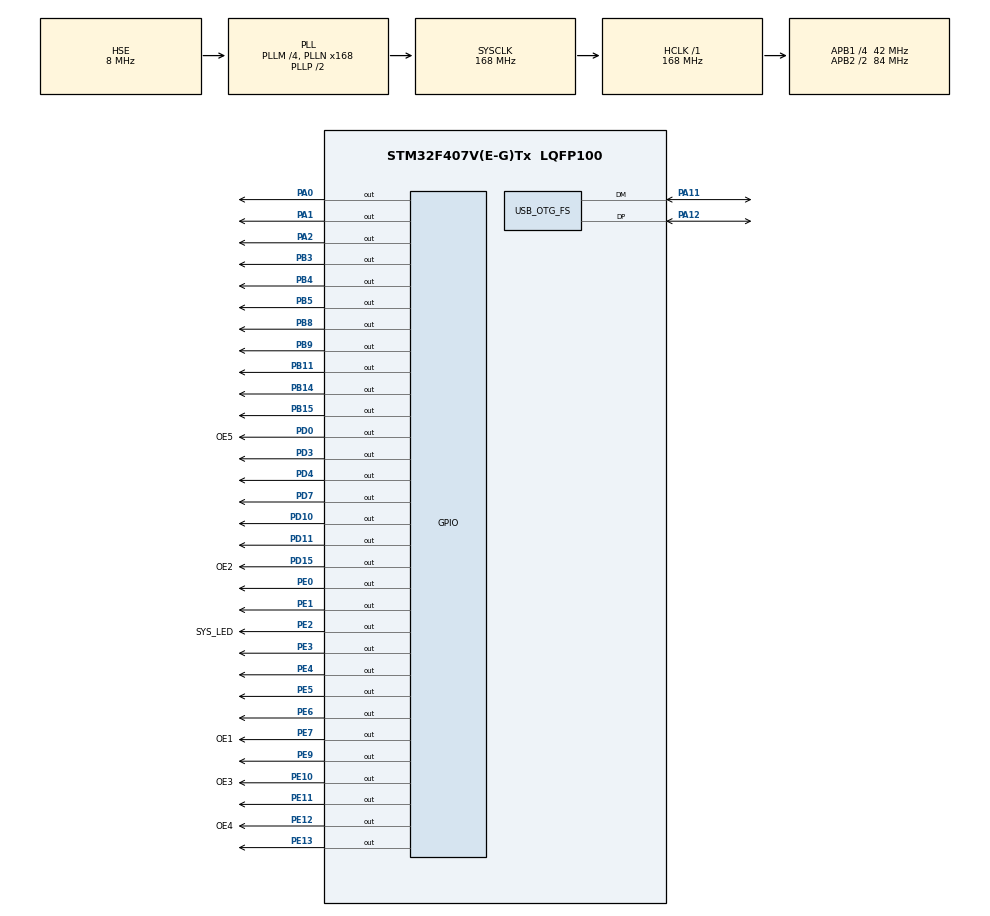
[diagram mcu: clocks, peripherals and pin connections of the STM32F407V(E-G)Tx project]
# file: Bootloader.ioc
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FREERTOS.Tasks01=defaultTask,24,128,StartDefaultTask,Default,NULL,Dynamic,NULL,NULL
Mcu.Family=STM32F4
Mcu.Name=STM32F407V(E-G)Tx
Mcu.Package=LQFP100
NVIC.OTG_FS_IRQn=true\:5\:0\:false\:false\:true\:true\:true\:true\:true
NVIC.PriorityGroup=NVIC_PRIORITYGROUP_4
PA0-WKUP.GPIO_PuPd=GPIO_PULLDOWN
PA0-WKUP.Signal=GPIO_Output
PA1.GPIO_PuPd=GPIO_PULLDOWN
PA1.Signal=GPIO_Output
PA11.Mode=Device_Only
PA11.Signal=USB_OTG_FS_DM
PA12.Mode=Device_Only
PA12.Signal=USB_OTG_FS_DP
PA2.GPIO_PuPd=GPIO_PULLDOWN
PA2.Signal=GPIO_Output
PB11.GPIO_PuPd=GPIO_PULLDOWN
PB11.Signal=GPIO_Output
PB14.GPIO_PuPd=GPIO_PULLDOWN
PB14.Signal=GPIO_Output
PB15.GPIO_PuPd=GPIO_PULLDOWN
PB15.Signal=GPIO_Output
PB3.GPIO_PuPd=GPIO_PULLDOWN
PB3.Signal=GPIO_Output
PB4.GPIO_PuPd=GPIO_PULLDOWN
PB4.Signal=GPIO_Output
PB5.GPIO_PuPd=GPIO_PULLDOWN
PB5.Signal=GPIO_Output
PB8.GPIO_PuPd=GPIO_PULLDOWN
PB8.Signal=GPIO_Output
PB9.GPIO_PuPd=GPIO_PULLDOWN
PB9.Signal=GPIO_Output
PD0.GPIO_Label=OE5
PD0.GPIO_PuPd=GPIO_NOPULL
PD0.GPIO_Speed=GPIO_SPEED_FREQ_MEDIUM
PD0.Signal=GPIO_Output
PD10.GPIO_PuPd=GPIO_PULLDOWN
PD10.Signal=GPIO_Output
PD11.GPIO_PuPd=GPIO_PULLDOWN
PD11.Signal=GPIO_Output
PD15.GPIO_Label=OE2
PD15.Signal=GPIO_Output
PD3.GPIO_PuPd=GPIO_PULLDOWN
PD3.Signal=GPIO_Output
PD4.GPIO_PuPd=GPIO_PULLDOWN
PD4.Signal=GPIO_Output
PD7.GPIO_PuPd=GPIO_PULLDOWN
PD7.Signal=GPIO_Output
PE0.GPIO_PuPd=GPIO_PULLDOWN
PE0.Signal=GPIO_Output
PE1.GPIO_PuPd=GPIO_PULLDOWN
PE1.Signal=GPIO_Output
PE10.GPIO_Label=OE3
PE10.GPIO_Speed=GPIO_SPEED_FREQ_MEDIUM
PE10.Signal=GPIO_Output
PE11.GPIO_PuPd=GPIO_PULLDOWN
PE11.Signal=GPIO_Output
PE12.GPIO_Label=OE4
PE12.GPIO_PuPd=GPIO_NOPULL
PE12.GPIO_Speed=GPIO_SPEED_FREQ_MEDIUM
PE12.Signal=GPIO_Output
PE13.GPIO_PuPd=GPIO_PULLDOWN
PE13.Signal=GPIO_Output
PE2.GPIO_Label=SYS_LED
PE2.GPIO_PuPd=GPIO_PULLUP
PE2.GPIO_Speed=GPIO_SPEED_FREQ_HIGH
PE2.PinState=GPIO_PIN_SET
PE2.Signal=GPIO_Output
PE3.GPIO_PuPd=GPIO_PULLDOWN
PE3.Signal=GPIO_Output
PE4.GPIO_PuPd=GPIO_PULLDOWN
PE4.Signal=GPIO_Output
PE5.GPIO_PuPd=GPIO_PULLDOWN
PE5.Signal=GPIO_Output
PE6.GPIO_PuPd=GPIO_PULLDOWN
PE6.Signal=GPIO_Output
PE7.GPIO_Label=OE1
PE7.GPIO_Speed=GPIO_SPEED_FREQ_MEDIUM
PE7.Signal=GPIO_Output
PE9.GPIO_PuPd=GPIO_PULLDOWN
PE9.Signal=GPIO_Output
PH0-OSC_IN.Mode=HSE-External-Oscillator
PH0-OSC_IN.Signal=RCC_OSC_IN
PH1-OSC_OUT.Mode=HSE-External-Oscillator
PH1-OSC_OUT.Signal=RCC_OSC_OUT
ProjectManager.HeapSize=0x1000
ProjectManager.StackSize=0x1000
ProjectManager.TargetToolchain=MDK-ARM V5.27
RCC.48MHZClocksFreq_Value=48000000
RCC.AHBFreq_Value=168000000
RCC.APB1CLKDivider=RCC_HCLK_DIV4
RCC.APB1Freq_Value=42000000
RCC.APB1TimFreq_Value=84000000
RCC.APB2CLKDivider=RCC_HCLK_DIV2
RCC.APB2Freq_Value=84000000
RCC.APB2TimFreq_Value=168000000
RCC.CortexFreq_Value=168000000
RCC.HCLKFreq_Value=168000000
RCC.HSE_VALUE=8000000
RCC.HSI_VALUE=16000000
RCC.LSE_VALUE=32768
RCC.PLLM=4
RCC.PLLN=168
RCC.PLLQ=7
RCC.SYSCLKFreq_VALUE=168000000
RCC.SYSCLKSource=RCC_SYSCLKSOURCE_PLLCLK
RCC.VCOOutputFreq_Value=336000000
USB_DEVICE.CLASS_NAME_FS=CDC
USB_DEVICE.VirtualMode-CDC_FS=Cdc
USB_DEVICE.VirtualModeFS=Cdc_FS
USB_OTG_FS.VirtualMode=Device_Only
VP_FREERTOS_VS_CMSIS_V2.Mode=CMSIS_V2
VP_USB_DEVICE_VS_USB_DEVICE_CDC_FS.Mode=CDC_FS
board=custom

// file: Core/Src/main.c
/* USER CODE BEGIN Header */
/**
  ******************************************************************************
  * @file           : main.c
  * @brief          : Main program body
  ******************************************************************************
  * @attention
  *
  * Copyright (c) 2024 STMicroelectronics.
  * All rights reserved.
  *
  * This software is licensed under terms that can be found in the LICENSE file
  * in the root directory of this software component.
  * If no LICENSE file comes with this software, it is provided AS-IS.
  *
  ******************************************************************************
  */
/* USER CODE END Header */
#include "main.h"
#include "cmsis_os.h"
#include "usb_device.h"

/* USER CODE BEGIN Includes */
#include "app.h"
/* USER CODE END Includes */

/* Definitions for defaultTask */
osThreadId_t defaultTaskHandle;
const osThreadAttr_t defaultTask_attributes = {
  .name = "defaultTask",
  .stack_size = 128 * 4,
  .priority = (osPriority_t) osPriorityNormal,
};

void SystemClock_Config(void);
static void MX_GPIO_Init(void);
void StartDefaultTask(void *argument);

int main(void)
{

  /* MCU Configuration--------------------------------------------------------*/

  /* Reset of all peripherals, Initializes the Flash interface and the Systick. */
  HAL_Init();

  /* Configure the system clock */
  SystemClock_Config();

  /* Initialize all configured peripherals */
  MX_GPIO_Init();

  /* Init scheduler */
  osKernelInitialize();

  /* Create the thread(s) */
  /* creation of defaultTask */
  defaultTaskHandle = osThreadNew(StartDefaultTask, NULL, &defaultTask_attributes);

  /* Start scheduler */
  osKernelStart();

  /* We should never get here as control is now taken by the scheduler */
  /* Infinite loop */
  while (1)
  {

  }
}

void SystemClock_Config(void)
{
  RCC_OscInitTypeDef RCC_OscInitStruct = {0};
  RCC_ClkInitTypeDef RCC_ClkInitStruct = {0};

  /** Configure the main internal regulator output voltage
  */
  __HAL_RCC_PWR_CLK_ENABLE();
  __HAL_PWR_VOLTAGESCALING_CONFIG(PWR_REGULATOR_VOLTAGE_SCALE1);

  /** Initializes the RCC Oscillators according to the specified parameters
  * in the RCC_OscInitTypeDef structure.
  */
  RCC_OscInitStruct.OscillatorType = RCC_OSCILLATORTYPE_HSE;
  RCC_OscInitStruct.HSEState = RCC_HSE_ON;
  RCC_OscInitStruct.PLL.PLLState = RCC_PLL_ON;
  RCC_OscInitStruct.PLL.PLLSource = RCC_PLLSOURCE_HSE;
  RCC_OscInitStruct.PLL.PLLM = 4;
  RCC_OscInitStruct.PLL.PLLN = 168;
  RCC_OscInitStruct.PLL.PLLP = RCC_PLLP_DIV2;
  RCC_OscInitStruct.PLL.PLLQ = 7;
  if (HAL_RCC_OscConfig(&RCC_OscInitStruct) != HAL_OK)
  {
    Error_Handler();
  }

  /** Initializes the CPU, AHB and APB buses clocks
  */
  RCC_ClkInitStruct.ClockType = RCC_CLOCKTYPE_HCLK|RCC_CLOCKTYPE_SYSCLK
                              |RCC_CLOCKTYPE_PCLK1|RCC_CLOCKTYPE_PCLK2;
  RCC_ClkInitStruct.SYSCLKSource = RCC_SYSCLKSOURCE_PLLCLK;
  RCC_ClkInitStruct.AHBCLKDivider = RCC_SYSCLK_DIV1;
  RCC_ClkInitStruct.APB1CLKDivider = RCC_HCLK_DIV4;
  RCC_ClkInitStruct.APB2CLKDivider = RCC_HCLK_DIV2;

  if (HAL_RCC_ClockConfig(&RCC_ClkInitStruct, FLASH_LATENCY_5) != HAL_OK)
  {
    Error_Handler();
  }
}

static void MX_GPIO_Init(void)
{
  GPIO_InitTypeDef GPIO_InitStruct = {0};

  /* GPIO Ports Clock Enable */
  __HAL_RCC_GPIOE_CLK_ENABLE();
  __HAL_RCC_GPIOH_CLK_ENABLE();
  __HAL_RCC_GPIOA_CLK_ENABLE();
  __HAL_RCC_GPIOB_CLK_ENABLE();
  __HAL_RCC_GPIOD_CLK_ENABLE();

  /*Configure GPIO pin Output Level */
  HAL_GPIO_WritePin(SYS_LED_GPIO_Port, SYS_LED_Pin, GPIO_PIN_SET);

  /*Configure GPIO pin Output Level */
  HAL_GPIO_WritePin(GPIOE, GPIO_PIN_3|GPIO_PIN_4|GPIO_PIN_5|GPIO_PIN_6
                          |OE1_Pin|GPIO_PIN_9|OE3_Pin|GPIO_PIN_11
                          |OE4_Pin|GPIO_PIN_13|GPIO_PIN_0|GPIO_PIN_1, GPIO_PIN_RESET);

  /*Configure GPIO pin Output Level */
  HAL_GPIO_WritePin(GPIOA, GPIO_PIN_0|GPIO_PIN_1|GPIO_PIN_2, GPIO_PIN_RESET);

  /*Configure GPIO pin Output Level */
  HAL_GPIO_WritePin(GPIOB, GPIO_PIN_11|GPIO_PIN_14|GPIO_PIN_15|GPIO_PIN_3
                          |GPIO_PIN_4|GPIO_PIN_5|GPIO_PIN_8|GPIO_PIN_9, GPIO_PIN_RESET);

  /*Configure GPIO pin Output Level */
  HAL_GPIO_WritePin(GPIOD, GPIO_PIN_10|GPIO_PIN_11|OE2_Pin|OE5_Pin
                          |GPIO_PIN_3|GPIO_PIN_4|GPIO_PIN_7, GPIO_PIN_RESET);

  /*Configure GPIO pin : SYS_LED_Pin */
  GPIO_InitStruct.Pin = SYS_LED_Pin;
  GPIO_InitStruct.Mode = GPIO_MODE_OUTPUT_PP;
  GPIO_InitStruct.Pull = GPIO_PULLUP;
  GPIO_InitStruct.Speed = GPIO_SPEED_FREQ_HIGH;
  HAL_GPIO_Init(SYS_LED_GPIO_Port, &GPIO_InitStruct);

  /*Configure GPIO pins : PE3 PE4 PE5 PE6
                           PE9 PE11 PE13 PE0
                           PE1 */
  GPIO_InitStruct.Pin = GPIO_PIN_3|GPIO_PIN_4|GPIO_PIN_5|GPIO_PIN_6
                          |GPIO_PIN_9|GPIO_PIN_11|GPIO_PIN_13|GPIO_PIN_0
                          |GPIO_PIN_1;
  GPIO_InitStruct.Mode = GPIO_MODE_OUTPUT_PP;
  GPIO_InitStruct.Pull = GPIO_PULLDOWN;
  GPIO_InitStruct.Speed = GPIO_SPEED_FREQ_LOW;
  HAL_GPIO_Init(GPIOE, &GPIO_InitStruct);

  /*Configure GPIO pins : PA0 PA1 PA2 */
  GPIO_InitStruct.Pin = GPIO_PIN_0|GPIO_PIN_1|GPIO_PIN_2;
  GPIO_InitStruct.Mode = GPIO_MODE_OUTPUT_PP;
  GPIO_InitStruct.Pull = GPIO_PULLDOWN;
  GPIO_InitStruct.Speed = GPIO_SPEED_FREQ_LOW;
  HAL_GPIO_Init(GPIOA, &GPIO_InitStruct);

  /*Configure GPIO pins : OE1_Pin OE3_Pin OE4_Pin */
  GPIO_InitStruct.Pin = OE1_Pin|OE3_Pin|OE4_Pin;
  GPIO_InitStruct.Mode = GPIO_MODE_OUTPUT_PP;
  GPIO_InitStruct.Pull = GPIO_NOPULL;
  GPIO_InitStruct.Speed = GPIO_SPEED_FREQ_MEDIUM;
  HAL_GPIO_Init(GPIOE, &GPIO_InitStruct);

  /*Configure GPIO pins : PB11 PB14 PB15 PB3
                           PB4 PB5 PB8 PB9 */
  GPIO_InitStruct.Pin = GPIO_PIN_11|GPIO_PIN_14|GPIO_PIN_15|GPIO_PIN_3
                          |GPIO_PIN_4|GPIO_PIN_5|GPIO_PIN_8|GPIO_PIN_9;
  GPIO_InitStruct.Mode = GPIO_MODE_OUTPUT_PP;
  GPIO_InitStruct.Pull = GPIO_PULLDOWN;
  GPIO_InitStruct.Speed = GPIO_SPEED_FREQ_LOW;
  HAL_GPIO_Init(GPIOB, &GPIO_InitStruct);

  /*Configure GPIO pins : PD10 PD11 PD3 PD4
                           PD7 */
  GPIO_InitStruct.Pin = GPIO_PIN_10|GPIO_PIN_11|GPIO_PIN_3|GPIO_PIN_4
                          |GPIO_PIN_7;
  GPIO_InitStruct.Mode = GPIO_MODE_OUTPUT_PP;
  GPIO_InitStruct.Pull = GPIO_PULLDOWN;
  GPIO_InitStruct.Speed = GPIO_SPEED_FREQ_LOW;
  HAL_GPIO_Init(GPIOD, &GPIO_InitStruct);

  /*Configure GPIO pin : OE2_Pin */
  GPIO_InitStruct.Pin = OE2_Pin;
  GPIO_InitStruct.Mode = GPIO_MODE_OUTPUT_PP;
  GPIO_InitStruct.Pull = GPIO_NOPULL;
  GPIO_InitStruct.Speed = GPIO_SPEED_FREQ_LOW;
  HAL_GPIO_Init(OE2_GPIO_Port, &GPIO_InitStruct);

  /*Configure GPIO pin : OE5_Pin */
  GPIO_InitStruct.Pin = OE5_Pin;
  GPIO_InitStruct.Mode = GPIO_MODE_OUTPUT_PP;
  GPIO_InitStruct.Pull = GPIO_NOPULL;
  GPIO_InitStruct.Speed = GPIO_SPEED_FREQ_MEDIUM;
  HAL_GPIO_Init(OE5_GPIO_Port, &GPIO_InitStruct);

}

void StartDefaultTask(void *argument)
{
  /* init code for USB_DEVICE */
  MX_USB_DEVICE_Init();
  /* USER CODE BEGIN 5 */
  app_init();
  /* Infinite loop */
  for(;;)
  {
	sys_run_led_toggle();
    osDelay(led_toggle_time_ms);
  }
  /* USER CODE END 5 */
}

void Error_Handler(void)
{
  __disable_irq();
  while (1)
  {
  }
}
